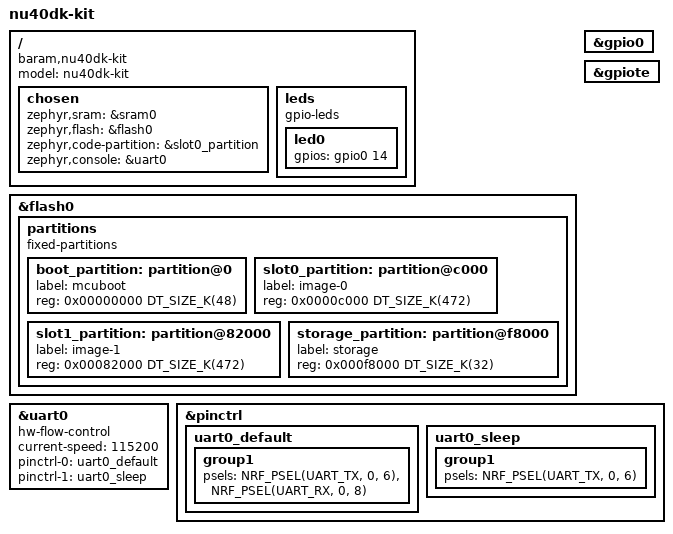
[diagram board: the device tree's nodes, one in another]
/dts-v1/;
#include <nordic/nrf52840_qiaa.dtsi>
#include "nu40dk_kit-pinctrl.dtsi"

/ {
	model = "nu40dk-kit";
	compatible = "baram,nu40dk-kit";

	chosen {
		zephyr,sram = &sram0;
		zephyr,flash = &flash0;
		zephyr,code-partition = &slot0_partition;
    zephyr,console = &uart0;
	};

  leds {
    compatible = "gpio-leds";
    led0: led0 {
      gpios = <&gpio0 14 0>;
    };
  };  
};

&flash0 {
	partitions {
		compatible = "fixed-partitions";
		#address-cells = <1>;
		#size-cells = <1>;

		boot_partition: partition@0 {
			label = "mcuboot";
			reg = <0x00000000 DT_SIZE_K(48)>;
		};

		slot0_partition: partition@c000 {
			label = "image-0";
			reg = <0x0000c000 DT_SIZE_K(472)>;
		};

		slot1_partition: partition@82000 {
			label = "image-1";
			reg = <0x00082000 DT_SIZE_K(472)>;
		};

		storage_partition: partition@f8000 {
			label = "storage";
			reg = <0x000f8000 DT_SIZE_K(32)>;
		};
	};
};

&gpio0 {
  status = "okay";
};

&gpiote {
  status = "okay";
};

&uart0 {
  status = "okay";
  hw-flow-control;
  current-speed = <115200>;
  pinctrl-0 = <&uart0_default>;
  pinctrl-1 = <&uart0_sleep>;
  pinctrl-names = "default", "sleep";
};

&pinctrl {
  uart0_default: uart0_default {
    group1 {
      psels = <NRF_PSEL(UART_TX, 0, 6)>, <NRF_PSEL(UART_RX, 0, 8)>;
    };
  };

  uart0_sleep: uart0_sleep {
    group1 {
      psels = <NRF_PSEL(UART_TX, 0, 6)>;
    };
  };
};
